# STM32U345 register map
File version: 1.0
CPU: CM33 r0p1, little endian, MPU, FPU, 4 interrupt priority bits
Registers are 32-bit, read-write, reset 0x0 unless marked. A register's access mark holds for its fields unless they carry their own. Offsets are from the block's base; [hi:lo] are bit positions; {n}, {i} and the like mark numbered series; 'fields as' and 'values as' point back to an identical list.

## TAMP — TAMP register block
Base 0x40007C00
Same registers: TAMP_S 0x50007C00
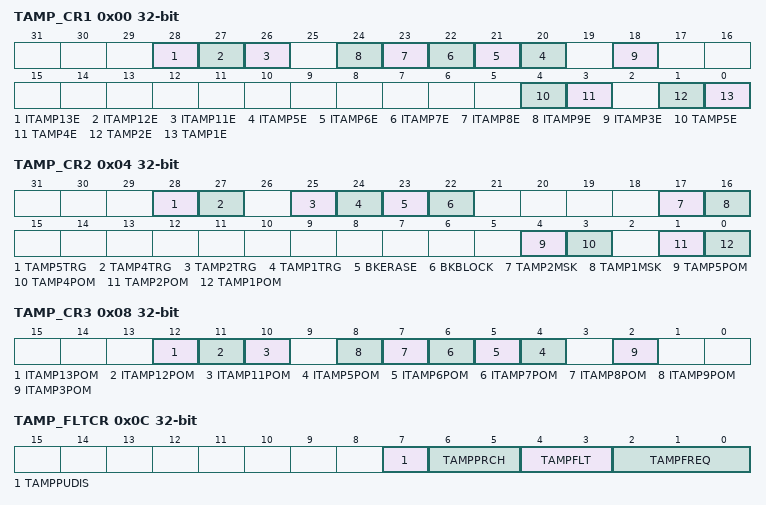
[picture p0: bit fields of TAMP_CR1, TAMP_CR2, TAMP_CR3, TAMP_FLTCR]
0x00 TAMP_CR1 — TAMP control register 1
  [28] ITAMP13E — Internal tamper i enable
    0=Internal tamper i disabled; 1=Internal tamper i enabled
  [27] ITAMP12E — Internal tamper i enable
    0=Internal tamper i disabled; 1=Internal tamper i enabled
  [26] ITAMP11E — Internal tamper i enable
    0=Internal tamper i disabled; 1=Internal tamper i enabled
  [n+15] ITAMP{n}E (n=5..9) — Internal tamper i enable
    0=Internal tamper i disabled; 1=Internal tamper i enabled
  [18] ITAMP3E — Internal tamper 3 enable
    0=Internal tamper 3 disabled; 1=Internal tamper 3 enabled
  [4] TAMP5E — Tamper detection on TAMP_INi enable
    0=Tamper detection on TAMP_INi disabled; 1=Tamper detection on TAMP_INi enabled
  [3] TAMP4E — Tamper detection on TAMP_INi enable
    values as TAMP5E
  [1] TAMP2E — Tamper detection on TAMP_INi enable
    values as TAMP5E
  [0] TAMP1E — Tamper detection on TAMP_INi enable
    values as TAMP5E
0x04 TAMP_CR2 — TAMP control register 2
  [28] TAMP5TRG — Active level for tamper 5 input
    0=If TAMPFLT[1:0] different 00, the tamper i input staying low triggers a tamper detection event; 1=If TAMPFLT[1:0] different 00 the tamper i input staying high triggers a tamper detection event
  [27] TAMP4TRG — Active level for tamper 5 input
    values as TAMP5TRG
  [25] TAMP2TRG — Active level for tamper 5 input
    values as TAMP5TRG
  [24] TAMP1TRG — Active level for tamper 5 input
    values as TAMP5TRG
  [23] BKERASE wo — Software confirmed tamper
  [22] BKBLOCK — Software potential tamper
    0=Backup registers and device secrets can be accessed if no tamper flag is set; 1=Backup registers and device secrets cannot be accessed
  [17] TAMP2MSK — Tamper i mask
    0=Tamper i event generates a trigger event and TAMPiF must be cleared by software to allow next tamper event detection; 1=Tamper i event generates a trigger event
  [16] TAMP1MSK — Tamper i mask
    values as TAMP2MSK
  [4] TAMP5POM — Tamper i potential mode
    0=Tamper i event detection is in confirmed mode; 1=Tamper i event detection is in potential mode
  [3] TAMP4POM — Tamper i potential mode
    values as TAMP5POM
  [1] TAMP2POM — Tamper i potential mode
    values as TAMP5POM
  [0] TAMP1POM — Tamper i potential mode
    values as TAMP5POM
0x08 TAMP_CR3 — TAMP control register 3
  [12] ITAMP13POM — Internal tamper i potential mode
    0=Internal tamper i event detection is in confirmed mode; 1=Internal tamper i event detection is in potential mode
  [11] ITAMP12POM — Internal tamper i potential mode
    values as ITAMP13POM
  [10] ITAMP11POM — Internal tamper i potential mode
    values as ITAMP13POM
  [n-1] ITAMP{n}POM (n=5..9) — Internal tamper i potential mode
    values as ITAMP13POM
  [2] ITAMP3POM — Internal tamper 3 potential mode
    0=Internal tamper 3 event detection is in confirmed mode; 1=Internal tamper 3 event detection is in potential mode
0x0C TAMP_FLTCR — TAMP filter control register
  [7] TAMPPUDIS — TAMP_INx pull-up disable
    0=Precharges TAMP_INx pins before sampling (enable internal pull-up); 1=Disables precharge of TAMP_INx pins
  [6:5] TAMPPRCH — TAMP_INx precharge duration
    0=1 RTCCLK cycle; 1=2 RTCCLK cycles; 2=4 RTCCLK cycles; 3=8 RTCCLK cycles
  [4:3] TAMPFLT — TAMP_INx filter count
    0=Tamper event is activated on edge of TAMP_INx input transitions to the active level (nointernal pull-up on TAMP_INx input); 1=Tamper event is activated after two consecutive samples at the active level; 2=Tamper event is activated after four consecutive samples at the active level; 3=Tamper event is activated after eight consecutive samples at the active level
  [2:0] TAMPFREQ — Tamper sampling frequency
    0=RTCCLK / 32768 (1 Hz when RTCCLK = 32768 Hz); 1=RTCCLK / 16384 (2 Hz when RTCCLK = 32768 Hz); 2=RTCCLK / 8192 (4 Hz when RTCCLK = 32768 Hz); 3=RTCCLK / 4096 (8 Hz when RTCCLK = 32768 Hz); 4=RTCCLK / 2048 (16 Hz when RTCCLK = 32768 Hz); 5=RTCCLK / 1024 (32 Hz when RTCCLK = 32768 Hz); 6=RTCCLK / 512 (64 Hz when RTCCLK = 32768 Hz); 7=RTCCLK / 256 (128 Hz when RTCCLK = 32768 Hz)
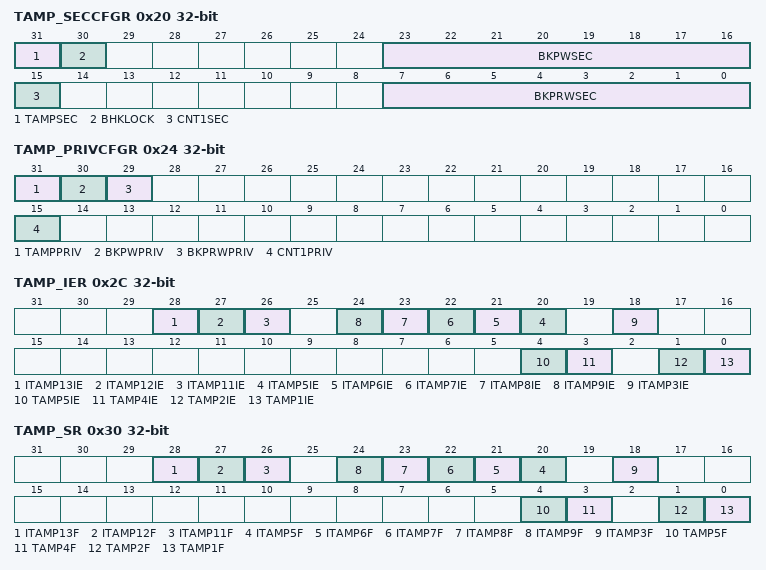
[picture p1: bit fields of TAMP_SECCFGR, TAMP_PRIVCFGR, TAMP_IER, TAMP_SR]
0x20 TAMP_SECCFGR — TAMP secure configuration register
  [31] TAMPSEC — Tamper protection (excluding monotonic counters and backup registers)
    0=Tamper configuration and interrupt can be written when the APB access is secure or nonsecure; 1=Tamper configuration and interrupt can be written only when the APB access is secure
  [30] BHKLOCK — Boot hardware key lock
    0=Backup registers from TAMP_BKP0R to TAMP_BKP7R can be accessed according to the protection zone they belong to; 1=Backup registers from TAMP_BKP0R to TAMP_BKP7R cannot be accessed neither in read, nor in write (they are read as 0, and write is ignored)
  [23:16] BKPWSEC — Backup register write protection offset
  [15] CNT1SEC — Monotonic counter 1 secure protection
    0=Monotonic counter 1 (TAMP_COUNT1R) can be read and written when the APB access is secure or nonsecure; 1=Monotonic counter 1 (TAMP_COUNT1R) can be read and written only when the APB access is secure
  [7:0] BKPRWSEC — Backup register read/write protection offset
0x24 TAMP_PRIVCFGR — TAMP privileged configuration register
  [31] TAMPPRIV — Tamper privileged protection (excluding backup registers)
    0=Tamper configuration and interrupt can be written with privileged or unprivileged access; 1=Tamper configuration and interrupt can be written only with privileged access
  [30] BKPWPRIV — Backup registers zone 2 privileged protection
    0=Backup registers zone 2 can be written with privileged or unprivileged access; 1=Backup registers zone 2 can be written only with privileged access
  [29] BKPRWPRIV — Backup registers zone 1 privileged protection
    0=Backup registers zone 1 can be written with privileged or unprivileged access; 1=Backup registers zone 1 can be written only with privileged access
  [15] CNT1PRIV — Monotonic counter 1 privileged protection
    0=Monotonic counter 1 (TAMP_COUNT1R) can be read and written with privileged or unprivileged access; 1=Monotonic counter 1 (TAMP_COUNT1R) can be read and written with privileged access
0x2C TAMP_IER — TAMP interrupt enable register
  [28] ITAMP13IE — Internal tamper i interrupt enable
    0=Internal tamper i interrupt disabled; 1=Internal tamper i interrupt enabled
  [27] ITAMP12IE — Internal tamper i interrupt enable
    values as ITAMP13IE
  [26] ITAMP11IE — Internal tamper i interrupt enable
    values as ITAMP13IE
  [n+15] ITAMP{n}IE (n=5..9) — Internal tamper i interrupt enable
    values as ITAMP13IE
  [18] ITAMP3IE — Internal tamper 3 interrupt enable
    0=Internal tamper 3 interrupt disabled; 1=Internal tamper 3 interrupt enabled
  [4] TAMP5IE — Tamper i interrupt enable
    0=Tamper i interrupt disabled; 1=Tamper i interrupt enabled
  [3] TAMP4IE — Tamper i interrupt enable
    0=Tamper i interrupt disabled; 1=Tamper i interrupt enabled
  [1] TAMP2IE — Tamper i interrupt enable
    0=Tamper i interrupt disabled; 1=Tamper i interrupt enabled
  [0] TAMP1IE — Tamper i interrupt enable
    0=Tamper i interrupt disabled; 1=Tamper i interrupt enabled
0x30 TAMP_SR — TAMP status register
  [28] ITAMP13F — Internal tamper i detection flag
  [27] ITAMP12F — Internal tamper i detection flag
  [26] ITAMP11F — Internal tamper i detection flag
  [n+15] ITAMP{n}F (n=5..9) — Internal tamper i detection flag
  [18] ITAMP3F — Internal tamper 3 detection flag
  [4] TAMP5F — Tamper i detection flag
  [3] TAMP4F — Tamper i detection flag
  [1] TAMP2F — Tamper i detection flag
  [0] TAMP1F — Tamper i detection flag
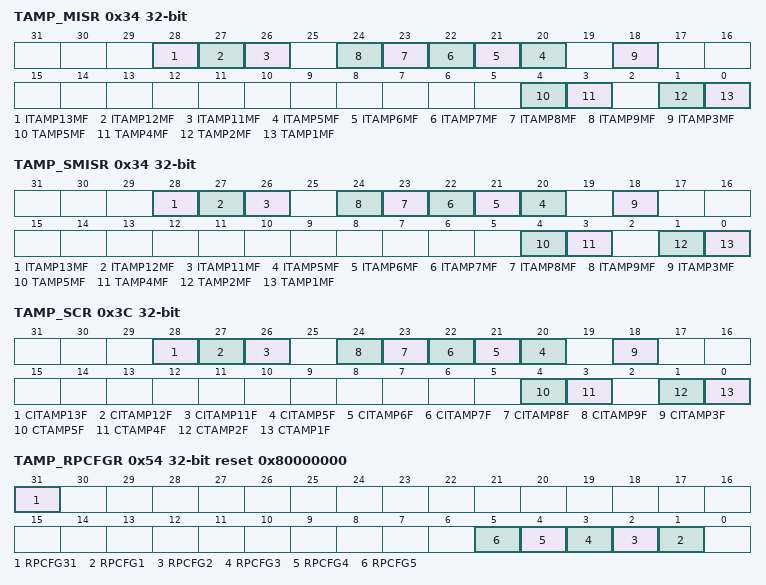
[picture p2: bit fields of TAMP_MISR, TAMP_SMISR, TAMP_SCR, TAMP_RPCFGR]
0x34 TAMP_MISR — TAMP nonsecure masked interrupt status register
  [28] ITAMP13MF — Internal tamper i nonsecure interrupt masked flag
  [27] ITAMP12MF — Internal tamper i nonsecure interrupt masked flag
  [26] ITAMP11MF — Internal tamper i nonsecure interrupt masked flag
  [n+15] ITAMP{n}MF (n=5..9) — Internal tamper i nonsecure interrupt masked flag
  [18] ITAMP3MF — Internal tamper 3 nonsecure interrupt masked flag
  [4] TAMP5MF — Tamper i nonsecure interrupt masked flag
  [3] TAMP4MF — Tamper i nonsecure interrupt masked flag
  [1] TAMP2MF — Tamper i nonsecure interrupt masked flag
  [0] TAMP1MF — Tamper i nonsecure interrupt masked flag
0x34 TAMP_SMISR (alternate view of TAMP_MISR) — TAMP secure masked interrupt status register
  [28] ITAMP13MF — Internal tamper i secure interrupt masked flag
  [27] ITAMP12MF — Internal tamper i secure interrupt masked flag
  [26] ITAMP11MF — Internal tamper i secure interrupt masked flag
  [n+15] ITAMP{n}MF (n=5..9) — Internal tamper i secure interrupt masked flag
  [18] ITAMP3MF — Internal tamper 3 secure interrupt masked flag
  [4] TAMP5MF — Tamper i secure interrupt masked flag
  [3] TAMP4MF — Tamper i secure interrupt masked flag
  [1] TAMP2MF — Tamper i secure interrupt masked flag
  [0] TAMP1MF — Tamper i secure interrupt masked flag
0x3C TAMP_SCR — TAMP status clear register
  [28] CITAMP13F — Internal tamper i detection flag clear
  [27] CITAMP12F — Internal tamper i detection flag clear
  [26] CITAMP11F — Internal tamper i detection flag clear
  [n+15] CITAMP{n}F (n=5..9) — Internal tamper i detection flag clear
  [18] CITAMP3F — Internal tamper 3 detectionflag clear
  [4] CTAMP5F — Tamper i detection flag clear
  [3] CTAMP4F — Tamper i detection flag clear
  [1] CTAMP2F — Tamper i detection flag clear
  [0] CTAMP1F — Tamper i detection flag clear
0x40 TAMP_COUNT1R ro — TAMP monotonic counter 1 register
  [31:0] COUNT — Monotonic counter
0x54 TAMP_RPCFGR reset 0x80000000 — TAMP resource protection register
  [31] RPCFG31 — Backup register protection
    0=Backup registers and BHKLOCK are not included in device secrets protected by the TAMP; 1=Backup registers and BHKLOCK are included in device secrets protected by the TAMP
  [n] RPCFG{n} (n=1..5) — Configurable resource i protection
    0=Resource i is not included in device secrets protected by the TAMP; 1=Resource i is included in device secrets protected by the TAMP
{0x100+4i} TAMP_BKP{i}R ro (i=0..31) — TAMP backup {i} register
  [31:0] BKP — Backup data
